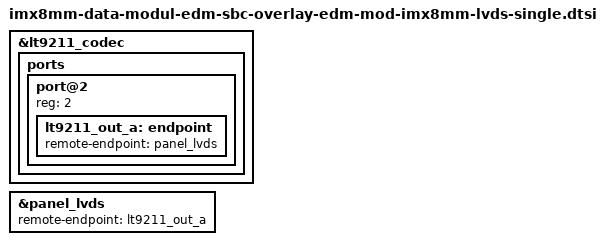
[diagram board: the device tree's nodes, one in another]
// SPDX-License-Identifier: (GPL-2.0+ OR MIT)
/*
 * Copyright 2026 Marek Vasut
 */

&lt9211_codec {
	ports {
		port@2 {
			reg = <2>;

			lt9211_out_a: endpoint {
				remote-endpoint = <&panel_lvds>;
			};
		};
	};
};

&panel_lvds {
	remote-endpoint = <&lt9211_out_a>;
};
